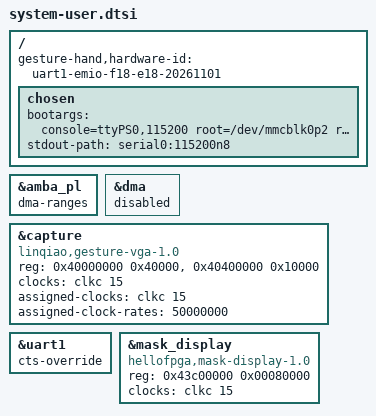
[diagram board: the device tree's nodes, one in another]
/* Integrated with the ACTUAL generated 2019.1 system-top.dts. */
/include/ "system-conf.dtsi"
/ {
 chosen {
  bootargs = "console=ttyPS0,115200 root=/dev/mmcblk0p2 rootfstype=ext4 rw rootwait";
  stdout-path = "serial0:115200n8";
 };
};
&amba_pl { dma-ranges; };
/* The custom driver is the ONLY owner of both memory windows. */
&dma { status = "disabled"; };
&capture {
 compatible = "linqiao,gesture-vga-1.0";
 reg = <0x40000000 0x40000>, <0x40400000 0x10000>;
 reg-names = "capture", "dma";
 clocks = <&clkc 15>;
 clock-names = "fclk0";
 assigned-clocks = <&clkc 15>;
 assigned-clock-rates = <50000000>;
 status = "okay";
};
/ { gesture-hand,hardware-id = "uart1-emio-f18-e18-20261101"; };
&uart1 {
 status = "okay";
 cts-override;
 /delete-property/ device_type;
 /delete-property/ port-number;
};
/* Amend the actual HSI-generated node; no duplicate 0x43c00000 node. */
&mask_display {
 compatible = "hellofpga,mask-display-1.0";
 reg = <0x43c00000 0x00080000>;
 clocks = <&clkc 15>;
 clock-names = "s_axi_aclk";
 status = "okay";
};
